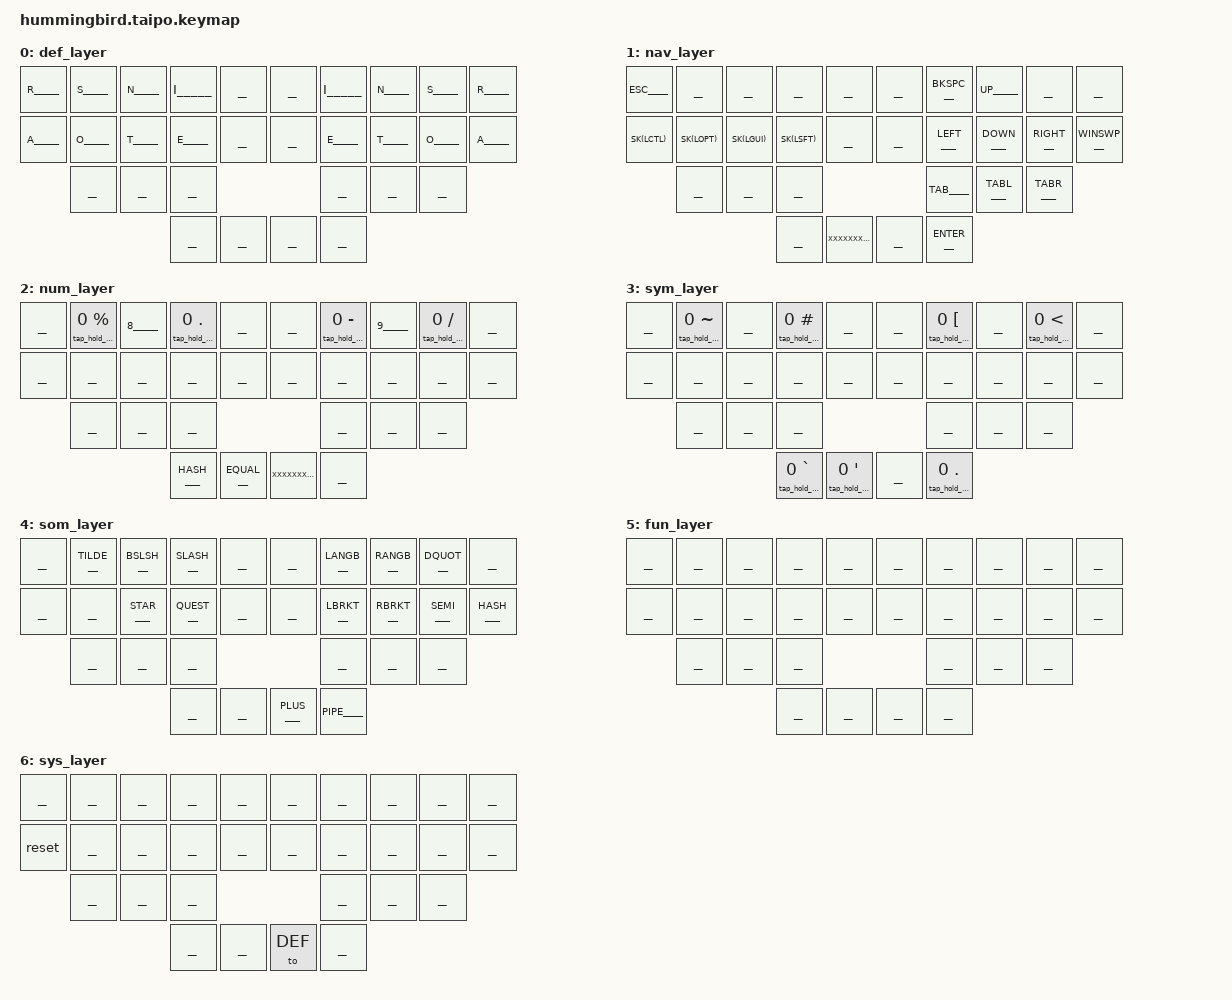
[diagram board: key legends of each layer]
#define HOST_OS 2

#include <behaviors.dtsi>
#include <dt-bindings/zmk/keys.h>
#include <dt-bindings/zmk/bt.h>

#include "./hummingbird.helpers.h"
#include "./helpers/nodefree.h"
#include "./helpers/keypos_20key.h"
#include "./keycodes.h"

/**
 * ----------------------------------------------
 * DEFAULT ALPHA LAYER
 * ----------------------------------------------
 */




ZMK_LAYER(def_layer,
// ╭─────────────┬─────────────┬─────────────┬─────────────┬─────────────╮   ╭─────────────┬─────────────┬─────────────┬─────────────┬─────────────╮
     _____R_____   _____S_____   _____N_____   _____I_____   ___________       ___________   _____I_____   _____N_____   _____S_____   _____R_____
// ├─────────────┼─────────────┼─────────────┼─────────────┼─────────────┤   ├─────────────┼─────────────┼─────────────┼─────────────┼─────────────┤
     _____A_____   _____O_____   _____T_____   _____E_____   ___________       ___________   _____E_____   _____T_____   _____O_____   _____A_____
// ├─────────────┼─────────────┼─────────────┼─────────────┼─────────────┤   ╰─────────────┼─────────────┼─────────────┼─────────────┼─────────────╯
                   ___________   ___________   ___________                                   ___________   ___________   ___________
//               ╰─────────────┼─────────────┼─────────────╯                               ╰─────────────┴─────────────┴─────────────╯
                                               ___________   ___________       ___________   ___________
//                                           ╰─────────────┴─────────────╯   ╰─────────────┴─────────────╯
)

/**
 * ----------------------------------------------
 * COMBO LEFT LOWER ALPHAS
 * ----------------------------------------------
 */

ZMK_COMBO(keylb, &kp B, LT3 LT2, DEF, 30)
ZMK_COMBO(keyly, &kp Y, LT1 LT0, DEF, 30)
ZMK_COMBO(keyll, &kp L, LB3 LB2, DEF, 30)
ZMK_COMBO(keylh, &kp H, LB1 LB0, DEF, 30)
ZMK_COMBO(keylu, &kp U, LB2 LB1, DEF, 30)
ZMK_COMBO(keylp, &kp P, LT2 LT1, DEF, 30)
ZMK_COMBO(keyld, &kp D, LB3 LB0, DEF, 30)
ZMK_COMBO(keylg, &kp G, LT3 LT0, DEF, 30)
ZMK_COMBO(keylz, &kp Z, LT3 LT1, DEF, 30)
ZMK_COMBO(keylf, &kp F, LT2 LT0, DEF, 30)
ZMK_COMBO(keylq, &kp Q, LB3 LB1, DEF, 30)
ZMK_COMBO(keylc, &kp C, LB2 LB0, DEF, 30)
ZMK_COMBO(keylx, &kp X, LT3 LB1, DEF, 30)
ZMK_COMBO(keylk, &kp K, LB2 LT0, DEF, 30)
ZMK_COMBO(keylv, &kp V, LT2 LB0, DEF, 30)
ZMK_COMBO(keylj, &kp J, LB3 LT1, DEF, 30)
ZMK_COMBO(keylm, &kp M, LT3 LB0, DEF, 30)
ZMK_COMBO(keylw, &kp W, LB3 LT0, DEF, 30)

/**
 * ----------------------------------------------
 * COMBO RIGHT LOWER ALPHAS
 * ----------------------------------------------
 */

ZMK_COMBO(keyrb, &kp B, RT3 RT2, DEF, 30)
ZMK_COMBO(keyry, &kp Y, RT1 RT0, DEF, 30)
ZMK_COMBO(keyrl, &kp L, RB3 RB2, DEF, 30)
ZMK_COMBO(keyrh, &kp H, RB1 RB0, DEF, 30)
ZMK_COMBO(keyru, &kp U, RB2 RB1, DEF, 30)
ZMK_COMBO(keyrp, &kp P, RT2 RT1, DEF, 30)
ZMK_COMBO(keyrd, &kp D, RB3 RB0, DEF, 30)
ZMK_COMBO(keyrg, &kp G, RT3 RT0, DEF, 30)
ZMK_COMBO(keyrz, &kp Z, RT3 RT1, DEF, 30)
ZMK_COMBO(keyrf, &kp F, RT2 RT0, DEF, 30)
ZMK_COMBO(keyrq, &kp Q, RB3 RB1, DEF, 30)
ZMK_COMBO(keyrc, &kp C, RB2 RB0, DEF, 30)
ZMK_COMBO(keyrx, &kp X, RT3 RB1, DEF, 30)
ZMK_COMBO(keyrk, &kp K, RB2 RT0, DEF, 30)
ZMK_COMBO(keyrv, &kp V, RT2 RB0, DEF, 30)
ZMK_COMBO(keyrj, &kp J, RB3 RT1, DEF, 30)
ZMK_COMBO(keyrm, &kp M, RT3 RB0, DEF, 30)
ZMK_COMBO(keyrw, &kp W, RB3 RT0, DEF, 30)





ZMK_COMBO(keyz,      &kp Z,        LT2 LT1, DEF, 30)

ZMK_COMBO(caps_word, &caps_word,   LM1 RM1, DEF, 80)









/**
 * ----------------------------------------------
 * NAV LAYER
 * ----------------------------------------------
 */
ZMK_COMBO(copy,      &kp LG(C), LM3 LM2, NAV, 20)
ZMK_COMBO(cut,       &kp LG(X), LM3 LM1, NAV, 20)
ZMK_COMBO(paste,     &kp LG(V), LM2 LM1, NAV, 20)
ZMK_COMBO(tab,       &kp TAB,   RM2 RM1, NAV, 40)

ZMK_LAYER(nav_layer,
// ╭─────────────┬─────────────┬─────────────┬─────────────┬─────────────╮   ╭─────────────┬─────────────┬─────────────┬─────────────┬─────────────╮
     ____ESC____   ___________   ___________   ___________   ___________       ___________   ___BKSPC___   ____UP_____   ___________   ___________
// ├─────────────┼─────────────┼─────────────┼─────────────┼─────────────┤   ├─────────────┼─────────────┼─────────────┼─────────────┼─────────────┤
     SK(LCTL)      SK(LOPT)      SK(LGUI)      SK(LSFT)      ___________       ___________   ___LEFT____   ___DOWN____   ___RIGHT___   __WINSWP___
// ├─────────────┼─────────────┼─────────────┼─────────────┼─────────────┤   ╰─────────────┼─────────────┼─────────────┼─────────────┼─────────────╯
                   ___________   ___________   ___________                                   ____TAB____   ___TABL____   ___TABR____
//               ╰─────────────┼─────────────┼─────────────╯                               ╰─────────────┴─────────────┴─────────────╯
                                               ___________   XXXXXXXXXXX       ___________   ___ENTER___
//                                           ╰─────────────┴─────────────╯   ╰─────────────┴─────────────╯
)

/**
 * ----------------------------------------------
 * ----------------------------------------------
 */
TAP_HOLD_MACRO(DOTCM, COMMA)
#define ___DOTCM___ &tap_hold_DOTCM 0 DOT

TAP_HOLD_MACRO(MINPLUS, PLUS)
#define __MINPLUS__ &tap_hold_MINPLUS 0 MINUS

TAP_HOLD_MACRO(SLASTAR, STAR)
#define __SLASTAR__ &tap_hold_SLASTAR 0 SLASH

TAP_HOLD_MACRO(PERCAR, CARET)
#define __PERCAR___ &tap_hold_PERCAR 0 PERCENT

ZMK_LAYER(num_layer,
// ╭─────────────┬─────────────┬─────────────┬─────────────┬─────────────╮   ╭─────────────┬─────────────┬─────────────┬─────────────┬─────────────╮
     ___________   __PERCAR___   _____8_____   ___DOTCM___   ___________       ___________   __MINPLUS__   _____9_____   __SLASTAR__   ___________
// ├─────────────┼─────────────┼─────────────┼─────────────┼─────────────┤   ├─────────────┼─────────────┼─────────────┼─────────────┼─────────────┤
     // HTLC(__6__)   HTLA(__4__)   HTLG(__2__)   HTLS(__0__)   ___________       ___________   HTRS(__1__)   HTRG(__3__)   HTRA(__5__)   HTRC(__7__)
     ___________   ___________   ___________   ___________   ___________       ___________   ___________   ___________   ___________   ___________
// ├─────────────┼─────────────┼─────────────┼─────────────┼─────────────┤   ╰─────────────┼─────────────┼─────────────┼─────────────┼─────────────╯
                   ___________   ___________   ___________                                   ___________   ___________   ___________
//               ╰─────────────┼─────────────┼─────────────╯                               ╰─────────────┴─────────────┴─────────────╯
                                               ___HASH____   ___EQUAL___       XXXXXXXXXXX   ___________
//                                           ╰─────────────┴─────────────╯   ╰─────────────┴─────────────╯
)


/**
 * ----------------------------------------------
 * SYM LAYER
 * ----------------------------------------------
 */
TAP_HOLD_MACRO(QUOTE, DOUBLE_QUOTES)
#define ___QUOTE___ &tap_hold_QUOTE 0 SINGLE_QUOTE

TAP_HOLD_MACRO(PARN, RIGHT_PARENTHESIS)
#define ___PARN____ &tap_hold_PARN 0 LEFT_PARENTHESIS

TAP_HOLD_MACRO(BRAC, RIGHT_BRACE)
#define ___BRAC____ &tap_hold_BRAC 0 LEFT_BRACE

TAP_HOLD_MACRO(BRKT, RIGHT_BRACKET)
#define ___BRKT____ &tap_hold_BRKT 0 LEFT_BRACKET

TAP_HOLD_MACRO(ANGB, GREATER_THAN)
#define ___ANGB____ &tap_hold_ANGB 0 LESS_THAN

TAP_HOLD_MACRO(TILCAR_, CARET)
#define __TILCAR___ &tap_hold_TILCAR_ 0 TILDE

TAP_HOLD_MACRO(HASHAT, AT_SIGN)
#define __HASHAT___ &tap_hold_HASHAT 0 HASH

TAP_HOLD_MACRO(BANGSTR, STAR)
#define __BANGSTR__ &tap_hold_BANGSTR 0 EXCLAMATION

TAP_HOLD_MACRO(PIPER, PERCENT)
#define ___PIPER___ &tap_hold_PIPER 0 PIPE

TAP_HOLD_MACRO(AMPEQ, EQUAL)
#define ___AMPEQ___ &tap_hold_AMPEQ 0 AMPERSAND

TAP_HOLD_MACRO(GRVDLR, DOLLAR)
#define __GRVDLR___ &tap_hold_GRVDLR 0 GRAVE

TAP_HOLD_MACRO(DOTHUH, QUESTION)
#define __DOTHUH___ &tap_hold_DOTHUH 0 DOT

TAP_HOLD_MACRO(COLSEMI, SEMICOLON)
#define __COLSEMI__ &tap_hold_COLSEMI 0 COLON

TAP_HOLD_MACRO(UNDRMIN, MINUS)
#define __UNDRMIN__ &tap_hold_UNDRMIN 0 UNDERSCORE

ZMK_LAYER(sym_layer,
// ╭─────────────┬─────────────┬─────────────┬─────────────┬─────────────╮   ╭─────────────┬─────────────┬─────────────┬─────────────┬─────────────╮
     ___________   __TILCAR___   ___________   __HASHAT___   ___________       ___________   ___BRKT____   ___________   ___ANGB____   ___________
// ├─────────────┼─────────────┼─────────────┼─────────────┼─────────────┤   ├─────────────┼─────────────┼─────────────┼─────────────┼─────────────┤
     // ___SLBSL___   __BANGSTR__   ___PIPER___   ___AMPEQ___   ___________       ___________   ___PARN____   ___BRAC____   __COLSEMI__   __UNDRMIN__
     ___________   ___________   ___________   ___________   ___________       ___________   ___________   ___________   ___________   ___________
// ├─────────────┼─────────────┼─────────────┼─────────────┼─────────────┤   ╰─────────────┼─────────────┼─────────────┼─────────────┼─────────────╯
                   ___________   ___________   ___________                                   ___________   ___________   ___________
//               ╰─────────────┼─────────────┼─────────────╯                               ╰─────────────┴─────────────┴─────────────╯
                                               __GRVDLR___   ___QUOTE___       ___________   __DOTHUH___
//                                           ╰─────────────┴─────────────╯   ╰─────────────┴─────────────╯
)

ZMK_LAYER(som_layer,
// ╭─────────────┬─────────────┬─────────────┬─────────────┬─────────────╮   ╭─────────────┬─────────────┬─────────────┬─────────────┬─────────────╮
     ___________   ___TILDE___   ___BSLSH___   ___SLASH___   ___________       ___________   ___LANGB___   ___RANGB___   ___DQUOT___   ___________
// ├─────────────┼─────────────┼─────────────┼─────────────┼─────────────┤   ├─────────────┼─────────────┼─────────────┼─────────────┼─────────────┤
     ___________   ___________   ___STAR____   ___QUEST___   ___________       ___________   ___LBRKT___   ___RBRKT___   ___SEMI____   ___HASH____
// ├─────────────┼─────────────┼─────────────┼─────────────┼─────────────┤   ╰─────────────┼─────────────┼─────────────┼─────────────┼─────────────╯
                   ___________   ___________   ___________                                   ___________   ___________   ___________
//               ╰─────────────┼─────────────┼─────────────╯                               ╰─────────────┴─────────────┴─────────────╯
                                               ___________   ___________       ___PLUS____   ___PIPE____
//                                           ╰─────────────┴─────────────╯   ╰─────────────┴─────────────╯
)

ZMK_LAYER(fun_layer,
// ╭─────────────┬─────────────┬─────────────┬─────────────┬─────────────╮   ╭─────────────┬─────────────┬─────────────┬─────────────┬─────────────╮
     ___________   ___________   ___________   ___________   ___________       ___________   ___________   ___________   ___________   ___________
// ├─────────────┼─────────────┼─────────────┼─────────────┼─────────────┤   ├─────────────┼─────────────┼─────────────┼─────────────┼─────────────┤
     ___________   ___________   ___________   ___________   ___________       ___________   ___________   ___________   ___________   ___________
// ├─────────────┼─────────────┼─────────────┼─────────────┼─────────────┤   ╰─────────────┼─────────────┼─────────────┼─────────────┼─────────────╯
                   ___________   ___________   ___________                                   ___________   ___________   ___________
//               ╰─────────────┼─────────────┼─────────────╯                               ╰─────────────┴─────────────┴─────────────╯
                                               ___________   ___________       ___________   ___________
//                                           ╰─────────────┴─────────────╯   ╰─────────────┴─────────────╯
)

ZMK_LAYER(sys_layer,
// ╭─────────────┬─────────────┬─────────────┬─────────────┬─────────────╮   ╭─────────────┬─────────────┬─────────────┬─────────────┬─────────────╮
     ___________   ___________   ___________   ___________   ___________       ___________   ___________   ___________   ___________   ___________
// ├─────────────┼─────────────┼─────────────┼─────────────┼─────────────┤   ├─────────────┼─────────────┼─────────────┼─────────────┼─────────────┤
     &reset        ___________   ___________   ___________   ___________       ___________   ___________   ___________   ___________   ___________
// ├─────────────┼─────────────┼─────────────┼─────────────┼─────────────┤   ╰─────────────┼─────────────┼─────────────┼─────────────┼─────────────╯
                   ___________   ___________   ___________                                   ___________   ___________   ___________
//               ╰─────────────┼─────────────┼─────────────╯                               ╰─────────────┴─────────────┴─────────────╯
                                               ___________   ___________       &to DEF       ___________
//                                           ╰─────────────┴─────────────╯   ╰─────────────┴─────────────╯
)

/*                KEY POSITIONS

  ╭────────────────────╮ ╭────────────────────╮
  │  0   1   2   3   4 │ │  5   6   7   8   9 │
  │ 10  11  12  13  14 │ │ 15  16  17  18  19 │
  │     20  21  22     │ │     23  24 25      │
  ╰───────────╮ 26  27 │ │ 28  29 ╭───────────╯
              ╰────────╯ ╰────────╯
*/

// ZMK_COMBO(to_sys, &to SYS, 11 12, SYM)



/**
 * TEMPLATES

// ╭─────────────┬─────────────┬─────────────┬─────────────┬─────────────╮   ╭─────────────┬─────────────┬─────────────┬─────────────┬─────────────╮
     ___________   ___________   ___________   ___________   ___________       ___________   ___________   ___________   ___________   ___________
// ├─────────────┼─────────────┼─────────────┼─────────────┼─────────────┤   ├─────────────┼─────────────┼─────────────┼─────────────┼─────────────┤
     ___________   ___________   ___________   ___________   ___________       ___________   ___________   ___________   ___________   ___________
// ├─────────────┼─────────────┼─────────────┼─────────────┼─────────────┤   ╰─────────────┼─────────────┼─────────────┼─────────────┼─────────────╯
                   ___________   ___________   ___________                                   ___________   ___________   ___________
//               ╰─────────────┼─────────────┼─────────────╯                               ╰─────────────┴─────────────┴─────────────╯
                                               ___________   ___________       ___________   ___________
//                                           ╰─────────────┴─────────────╯   ╰─────────────┴─────────────╯

// ╭─────────────┬─────────────┬─────────────┬─────────────┬─────────────╮   ╭─────────────┬─────────────┬─────────────┬─────────────┬─────────────╮
     XXXXXXXXXXX   XXXXXXXXXXX   XXXXXXXXXXX   XXXXXXXXXXX       XXXXXXXXXXX   XXXXXXXXXXX   XXXXXXXXXXX   XXXXXXXXXXX   XXXXXXXXXXX
// ├─────────────┼─────────────┼─────────────┼─────────────┼─────────────┤   ├─────────────┼─────────────┼─────────────┼─────────────┼─────────────┤
     XXXXXXXXXXX   XXXXXXXXXXX   XXXXXXXXXXX   XXXXXXXXXXX   XXXXXXXXXXX       XXXXXXXXXXX   XXXXXXXXXXX   XXXXXXXXXXX   XXXXXXXXXXX   XXXXXXXXXXX
// ├─────────────┼─────────────┼─────────────┼─────────────┼─────────────┤   ╰─────────────┼─────────────┼─────────────┼─────────────┼─────────────╯
                   XXXXXXXXXXX   XXXXXXXXXXX   XXXXXXXXXXX                                   XXXXXXXXXXX   XXXXXXXXXXX   XXXXXXXXXXX
//               ╰─────────────┼─────────────┼─────────────╯                               ╰─────────────┴─────────────┴─────────────╯
                                               XXXXXXXXXXX   XXXXXXXXXXX       XXXXXXXXXXX   XXXXXXXXXXX
//                                           ╰─────────────┴─────────────╯   ╰─────────────┴─────────────╯
*/
